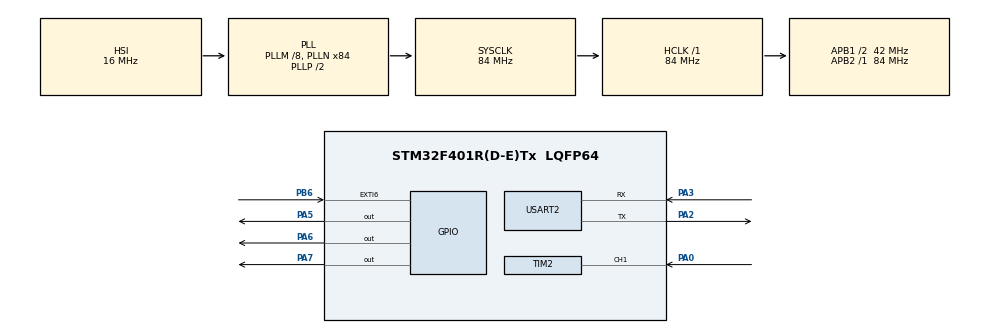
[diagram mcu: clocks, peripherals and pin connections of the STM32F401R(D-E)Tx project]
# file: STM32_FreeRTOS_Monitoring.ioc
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FREERTOS.Tasks01=defaultTask,0,128,StartDefaultTask,Default,NULL,Dynamic,NULL,NULL;Task_DHT11,0,128,StartTask02,Default,NULL,Dynamic,NULL,NULL;Task_HC_SR04,0,128,StartTask03,Default,NULL,Dynamic,NULL,NULL;Task_LED_Alert,2,128,StartTask04,Default,NULL,Dynamic,NULL,NULL
Mcu.Family=STM32F4
Mcu.Name=STM32F401R(D-E)Tx
Mcu.Package=LQFP64
NVIC.EXTI9_5_IRQn=true\:5\:0\:false\:false\:true\:true\:true
NVIC.PriorityGroup=NVIC_PRIORITYGROUP_4
NVIC.TIM2_IRQn=true\:5\:0\:false\:false\:true\:true\:true
PA0-WKUP.Signal=S_TIM2_CH1_ETR
PA2.Mode=Asynchronous
PA2.Signal=USART2_TX
PA3.Mode=Asynchronous
PA3.Signal=USART2_RX
PA5.Signal=GPIO_Output
PA6.GPIO_ModeDefaultOutputPP=GPIO_MODE_OUTPUT_OD
PA6.GPIO_PuPd=GPIO_PULLUP
PA6.Signal=GPIO_Output
PA7.Signal=GPIO_Output
PB6.Signal=GPXTI6
PC14-OSC32_IN.Mode=LSE-External-Oscillator
PC14-OSC32_IN.Signal=RCC_OSC32_IN
PC15-OSC32_OUT.Mode=LSE-External-Oscillator
PC15-OSC32_OUT.Signal=RCC_OSC32_OUT
PH0\ -\ OSC_IN.Mode=HSE-External-Oscillator
PH0\ -\ OSC_IN.Signal=RCC_OSC_IN
PH1\ -\ OSC_OUT.Mode=HSE-External-Oscillator
PH1\ -\ OSC_OUT.Signal=RCC_OSC_OUT
ProjectManager.HeapSize=0x200
ProjectManager.StackSize=0x400
ProjectManager.TargetToolchain=MDK-ARM V5
RCC.48MHZClocksFreq_Value=42000000
RCC.AHBFreq_Value=84000000
RCC.APB1CLKDivider=RCC_HCLK_DIV2
RCC.APB1Freq_Value=42000000
RCC.APB1TimFreq_Value=84000000
RCC.APB2Freq_Value=84000000
RCC.APB2TimFreq_Value=84000000
RCC.CortexFreq_Value=84000000
RCC.HCLKFreq_Value=84000000
RCC.HSE_VALUE=25000000
RCC.HSI_VALUE=16000000
RCC.PLLM=8
RCC.PLLN=84
RCC.SYSCLKFreq_VALUE=84000000
RCC.SYSCLKSource=RCC_SYSCLKSOURCE_PLLCLK
RCC.VCOOutputFreq_Value=168000000
SH.S_TIM2_CH1_ETR.0=TIM2_CH1,Input_Capture1_from_TI1
TIM2.Channel-Input_Capture1_from_TI1=TIM_CHANNEL_1
USART2.VirtualMode=VM_ASYNC
VP_FREERTOS_VS_ENABLE.Mode=Enabled
board=custom

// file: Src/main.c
/* USER CODE BEGIN Header */
/**
  ******************************************************************************
  * @file           : main.c
  * @brief          : Main program body
  ******************************************************************************
  * This notice applies to any and all portions of this file
  * that are not between comment pairs USER CODE BEGIN and
  * USER CODE END. Other portions of this file, whether
  * inserted by the user or by software development tools
  * are owned by their respective copyright owners.
  *
  * Copyright (c) 2024 STMicroelectronics International N.V.
  * All rights reserved.
  *
  * Redistribution and use in source and binary forms, with or without
  * modification, are permitted, provided that the following conditions are met:
  *
  * 1. Redistribution of source code must retain the above copyright notice,
  *    this list of conditions and the following disclaimer.
  * 2. Redistributions in binary form must reproduce the above copyright notice,
  *    this list of conditions and the following disclaimer in the documentation
  *    and/or other materials provided with the distribution.
  * 3. Neither the name of STMicroelectronics nor the names of other
  *    contributors to this software may be used to endorse or promote products
  *    derived from this software without specific written permission.
  * 4. This software, including modifications and/or derivative works of this
  *    software, must execute solely and exclusively on microcontroller or
  *    microprocessor devices manufactured by or for STMicroelectronics.
  * 5. Redistribution and use of this software other than as permitted under
  *    this license is void and will automatically terminate your rights under
  *    this license.
  *
  * THIS SOFTWARE IS PROVIDED BY STMICROELECTRONICS AND CONTRIBUTORS "AS IS"
  * AND ANY EXPRESS, IMPLIED OR STATUTORY WARRANTIES, INCLUDING, BUT NOT
  * LIMITED TO, THE IMPLIED WARRANTIES OF MERCHANTABILITY, FITNESS FOR A
  * PARTICULAR PURPOSE AND NON-INFRINGEMENT OF THIRD PARTY INTELLECTUAL PROPERTY
  * RIGHTS ARE DISCLAIMED TO THE FULLEST EXTENT PERMITTED BY LAW. IN NO EVENT
  * SHALL STMICROELECTRONICS OR CONTRIBUTORS BE LIABLE FOR ANY DIRECT, INDIRECT,
  * INCIDENTAL, SPECIAL, EXEMPLARY, OR CONSEQUENTIAL DAMAGES (INCLUDING, BUT NOT
  * LIMITED TO, PROCUREMENT OF SUBSTITUTE GOODS OR SERVICES; LOSS OF USE, DATA,
  * OR PROFITS; OR BUSINESS INTERRUPTION) HOWEVER CAUSED AND ON ANY THEORY OF
  * LIABILITY, WHETHER IN CONTRACT, STRICT LIABILITY, OR TORT (INCLUDING
  * NEGLIGENCE OR OTHERWISE) ARISING IN ANY WAY OUT OF THE USE OF THIS SOFTWARE,
  * EVEN IF ADVISED OF THE POSSIBILITY OF SUCH DAMAGE.
  *
  ******************************************************************************
  */
/* USER CODE END Header */

#include "main.h"
#include "cmsis_os.h"
#include <string.h>

#define DHT11_OK 0
#define TRIG_PIN GPIO_PIN_0  // PA0: Trigger pin
#define TRIG_PORT GPIOA

#define ECHO_PIN GPIO_PIN_1  // PA1: Echo pin
#define ECHO_PORT GPIOA
TIM_HandleTypeDef htim2;

UART_HandleTypeDef huart2;

osThreadId defaultTaskHandle;
osThreadId Task_DHT11Handle;
osThreadId Task_HC_SR04Handle;
osThreadId Task_LED_AlertHandle;

/* USER CODE BEGIN PV */
float temperature, humidity, distance;
int alertThresholdTemp = 30;  // Temperature alert threshold (in Celsius).
int alertThresholdDist = 20;  // Distance alert threshold (in cm).

volatile uint32_t start_time = 0, end_time = 0;
volatile float distanceObject = 0;
/* USER CODE END PV */

void SystemClock_Config(void);
static void MX_GPIO_Init(void);
static void MX_TIM2_Init(void);
static void MX_USART2_UART_Init(void);
void StartDefaultTask(void const * argument);
void StartTask02(void const * argument);
void StartTask03(void const * argument);
void StartTask04(void const * argument);

/* USER CODE BEGIN PFP */
void ReadDHT11(void);
void ReadHC_SR04(void);
void LED_Alert(void);
void HC_SR04_GetDistance(void);
void delay_us(uint16_t us);
void DHT11_Read(void);

/* USER CODE END PFP */

int main(void)
{

  /* MCU Configuration--------------------------------------------------------*/

  /* Reset of all peripherals, Initializes the Flash interface and the Systick. */
  HAL_Init();

  /* Configure the system clock */
  SystemClock_Config();

  /* Initialize all configured peripherals */
  MX_GPIO_Init();
  MX_TIM2_Init();
  MX_USART2_UART_Init();

  /* Create the thread(s) */
  /* definition and creation of defaultTask */
  osThreadDef(defaultTask, StartDefaultTask, osPriorityNormal, 0, 128);
  defaultTaskHandle = osThreadCreate(osThread(defaultTask), NULL);

  /* definition and creation of Task_DHT11 */
  osThreadDef(Task_DHT11, StartTask02, osPriorityNormal, 0, 128);
  Task_DHT11Handle = osThreadCreate(osThread(Task_DHT11), NULL);

  /* definition and creation of Task_HC_SR04 */
  osThreadDef(Task_HC_SR04, StartTask03, osPriorityNormal, 0, 128);
  Task_HC_SR04Handle = osThreadCreate(osThread(Task_HC_SR04), NULL);

  /* definition and creation of Task_LED_Alert */
  osThreadDef(Task_LED_Alert, StartTask04, osPriorityHigh, 0, 128);
  Task_LED_AlertHandle = osThreadCreate(osThread(Task_LED_Alert), NULL);

  /* Start scheduler */
  osKernelStart();

  /* We should never get here as control is now taken by the scheduler */

  /* Infinite loop */
  while (1)
  {

  }
}
void StartDefaultTask(void const * argument)
{
  for(;;)
  {
    osDelay(1);
  }
}

void StartTask02(void const * argument)
{
  for(;;)
  {
    ReadDHT11();
    osDelay(1000);  // Delay for 1 second to read the DHT11 sensor again.
  }
}

void StartTask03(void const * argument)
{
  for(;;)
  {
    ReadHC_SR04();
    osDelay(1000);  // Delay for 1 second to measure distance again.
  }
}

void StartTask04(void const * argument)
{
  for(;;)
  {
    LED_Alert();
    osDelay(500);  // Check LED alert every 500ms.
  }
}

/* USER CODE BEGIN 0 */

/* Read data from DHT11 sensor */
void ReadDHT11(void)
{
  int result ;//= DHT11_Read(&temperature, &humidity);
  if(result == DHT11_OK)
  {
    // Send data over UART for debugging
    char buffer[50];
    snprintf(buffer, sizeof(buffer), "Temp: %.2f C, Humidity: %.2f%%\r\n", temperature, humidity);
    HAL_UART_Transmit(&huart2, (uint8_t*)buffer, strlen(buffer), HAL_MAX_DELAY);
  }
  else
  {
    // Handle sensor read error
    HAL_UART_Transmit(&huart2, (uint8_t*)"Error reading DHT11\r\n", 21, HAL_MAX_DELAY);
  }
}

/* Measure distance using HC-SR04 */
void ReadHC_SR04(void)
{
  HC_SR04_GetDistance();
  // Send distance data over UART for debugging
  char buffer[50];
  snprintf(buffer, sizeof(buffer), "Distance: %.2f cm\r\n", distance);
  HAL_UART_Transmit(&huart2, (uint8_t*)buffer, strlen(buffer), HAL_MAX_DELAY);
}

/* LED alert logic based on sensor data */
void LED_Alert(void)
{
  if (temperature > alertThresholdTemp || distance < alertThresholdDist)
  {
    HAL_GPIO_WritePin(GPIOA, GPIO_PIN_5, GPIO_PIN_SET);  // Turn ON LED
  }
  else
  {
    HAL_GPIO_WritePin(GPIOA, GPIO_PIN_5, GPIO_PIN_RESET);  // Turn OFF LED
  }
}
void HC_SR04_GetDistance(void)
{
    // Send a 10us HIGH pulse on Trigger pin
    HAL_GPIO_WritePin(TRIG_PORT, TRIG_PIN, GPIO_PIN_SET);
    delay_us(10);
    HAL_GPIO_WritePin(TRIG_PORT, TRIG_PIN, GPIO_PIN_RESET);

    // Wait for Echo to go HIGH (start of pulse)
    while (HAL_GPIO_ReadPin(ECHO_PORT, ECHO_PIN) == GPIO_PIN_RESET);

    start_time = __HAL_TIM_GET_COUNTER(&htim2);  // Capture start time

    // Wait for Echo to go LOW (end of pulse)
    while (HAL_GPIO_ReadPin(ECHO_PORT, ECHO_PIN) == GPIO_PIN_SET);

    end_time = __HAL_TIM_GET_COUNTER(&htim2);  // Capture end time

    // Calculate the distance (speed of sound = 340 m/s or 0.034 cm/us)
    distanceObject = (end_time - start_time) * 0.034 / 2.0;
    // PrИparer et envoyer les donnИes de distance via UART
    char msg[50];
    snprintf(msg, sizeof(msg), "Distance: %.2f cm\n", distanceObject);
    HAL_UART_Transmit(&huart2, (uint8_t*)msg, strlen(msg), HAL_MAX_DELAY);
}

void delay_us(uint16_t us)
{
    __HAL_TIM_SET_COUNTER(&htim2, 0);  // Reset the timer counter
    while (__HAL_TIM_GET_COUNTER(&htim2) < us);  // Wait for the counter to reach 'us'
}

void SystemClock_Config(void)
{
  RCC_OscInitTypeDef RCC_OscInitStruct = {0};
  RCC_ClkInitTypeDef RCC_ClkInitStruct = {0};

  /**Configure the main internal regulator output voltage
  */
  __HAL_RCC_PWR_CLK_ENABLE();
  __HAL_PWR_VOLTAGESCALING_CONFIG(PWR_REGULATOR_VOLTAGE_SCALE2);
  /**Initializes the CPU, AHB and APB busses clocks
  */
  RCC_OscInitStruct.OscillatorType = RCC_OSCILLATORTYPE_HSI;
  RCC_OscInitStruct.HSIState = RCC_HSI_ON;
  RCC_OscInitStruct.HSICalibrationValue = RCC_HSICALIBRATION_DEFAULT;
  RCC_OscInitStruct.PLL.PLLState = RCC_PLL_ON;
  RCC_OscInitStruct.PLL.PLLSource = RCC_PLLSOURCE_HSI;
  RCC_OscInitStruct.PLL.PLLM = 8;
  RCC_OscInitStruct.PLL.PLLN = 84;
  RCC_OscInitStruct.PLL.PLLP = RCC_PLLP_DIV2;
  RCC_OscInitStruct.PLL.PLLQ = 4;
  if (HAL_RCC_OscConfig(&RCC_OscInitStruct) != HAL_OK)
  {
    Error_Handler();
  }
  /**Initializes the CPU, AHB and APB busses clocks
  */
  RCC_ClkInitStruct.ClockType = RCC_CLOCKTYPE_HCLK|RCC_CLOCKTYPE_SYSCLK
                              |RCC_CLOCKTYPE_PCLK1|RCC_CLOCKTYPE_PCLK2;
  RCC_ClkInitStruct.SYSCLKSource = RCC_SYSCLKSOURCE_PLLCLK;
  RCC_ClkInitStruct.AHBCLKDivider = RCC_SYSCLK_DIV1;
  RCC_ClkInitStruct.APB1CLKDivider = RCC_HCLK_DIV2;
  RCC_ClkInitStruct.APB2CLKDivider = RCC_HCLK_DIV1;

  if (HAL_RCC_ClockConfig(&RCC_ClkInitStruct, FLASH_LATENCY_2) != HAL_OK)
  {
    Error_Handler();
  }
}

static void MX_TIM2_Init(void)
{

  TIM_MasterConfigTypeDef sMasterConfig = {0};
  TIM_IC_InitTypeDef sConfigIC = {0};

  htim2.Instance = TIM2;
  htim2.Init.Prescaler = 0;
  htim2.Init.CounterMode = TIM_COUNTERMODE_UP;
  htim2.Init.Period = 0;
  htim2.Init.ClockDivision = TIM_CLOCKDIVISION_DIV1;
  if (HAL_TIM_IC_Init(&htim2) != HAL_OK)
  {
    Error_Handler();
  }
  sMasterConfig.MasterOutputTrigger = TIM_TRGO_RESET;
  sMasterConfig.MasterSlaveMode = TIM_MASTERSLAVEMODE_DISABLE;
  if (HAL_TIMEx_MasterConfigSynchronization(&htim2, &sMasterConfig) != HAL_OK)
  {
    Error_Handler();
  }
  sConfigIC.ICPolarity = TIM_INPUTCHANNELPOLARITY_RISING;
  sConfigIC.ICSelection = TIM_ICSELECTION_DIRECTTI;
  sConfigIC.ICPrescaler = TIM_ICPSC_DIV1;
  sConfigIC.ICFilter = 0;
  if (HAL_TIM_IC_ConfigChannel(&htim2, &sConfigIC, TIM_CHANNEL_1) != HAL_OK)
  {
    Error_Handler();
  }

}

static void MX_USART2_UART_Init(void)
{

  huart2.Instance = USART2;
  huart2.Init.BaudRate = 115200;
  huart2.Init.WordLength = UART_WORDLENGTH_8B;
  huart2.Init.StopBits = UART_STOPBITS_1;
  huart2.Init.Parity = UART_PARITY_NONE;
  huart2.Init.Mode = UART_MODE_TX_RX;
  huart2.Init.HwFlowCtl = UART_HWCONTROL_NONE;
  huart2.Init.OverSampling = UART_OVERSAMPLING_16;
  if (HAL_UART_Init(&huart2) != HAL_OK)
  {
    Error_Handler();
  }

}

static void MX_GPIO_Init(void)
{
  GPIO_InitTypeDef GPIO_InitStruct = {0};

  /* GPIO Ports Clock Enable */
  __HAL_RCC_GPIOC_CLK_ENABLE();
  __HAL_RCC_GPIOH_CLK_ENABLE();
  __HAL_RCC_GPIOA_CLK_ENABLE();
  __HAL_RCC_GPIOB_CLK_ENABLE();

  /*Configure GPIO pin Output Level */
  HAL_GPIO_WritePin(GPIOA, GPIO_PIN_5|GPIO_PIN_6|GPIO_PIN_7, GPIO_PIN_RESET);

  /*Configure GPIO pins : PA5 PA7 */
  GPIO_InitStruct.Pin = GPIO_PIN_5|GPIO_PIN_7;
  GPIO_InitStruct.Mode = GPIO_MODE_OUTPUT_PP;
  GPIO_InitStruct.Pull = GPIO_NOPULL;
  GPIO_InitStruct.Speed = GPIO_SPEED_FREQ_LOW;
  HAL_GPIO_Init(GPIOA, &GPIO_InitStruct);

  /*Configure GPIO pin : PA6 */
  GPIO_InitStruct.Pin = GPIO_PIN_6;
  GPIO_InitStruct.Mode = GPIO_MODE_OUTPUT_OD;
  GPIO_InitStruct.Pull = GPIO_PULLUP;
  GPIO_InitStruct.Speed = GPIO_SPEED_FREQ_LOW;
  HAL_GPIO_Init(GPIOA, &GPIO_InitStruct);

  /*Configure GPIO pin : PB6 */
  GPIO_InitStruct.Pin = GPIO_PIN_6;
  GPIO_InitStruct.Mode = GPIO_MODE_IT_RISING;
  GPIO_InitStruct.Pull = GPIO_NOPULL;
  HAL_GPIO_Init(GPIOB, &GPIO_InitStruct);

  /* EXTI interrupt init*/
  HAL_NVIC_SetPriority(EXTI9_5_IRQn, 5, 0);
  HAL_NVIC_EnableIRQ(EXTI9_5_IRQn);

}

void StartDefaultTask(void const * argument)
{

  for(;;)
  {
    osDelay(1);
  }
}

void StartTask02(void const * argument)
{
  for(;;)
  {
    osDelay(1);
  }
}

void StartTask03(void const * argument)
{
  for(;;)
  {
    osDelay(1);
  }
}

void StartTask04(void const * argument)
{
  for(;;)
  {
    osDelay(1);
  }
}

void Error_Handler(void)
{
}

/************************ (C) COPYRIGHT STMicroelectronics *****END OF FILE****/
